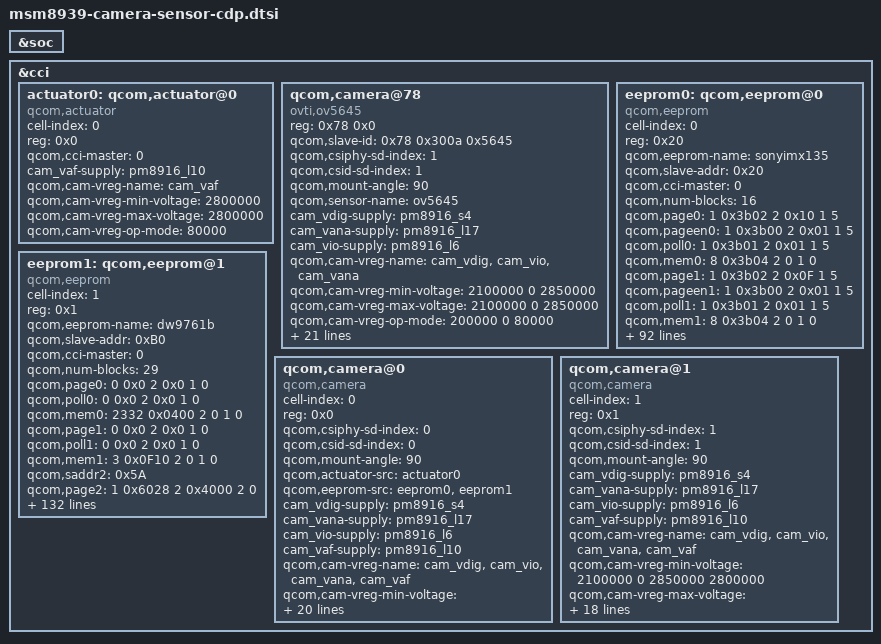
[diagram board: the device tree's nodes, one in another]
/*
 * Copyright (c) 2014-2015, The Linux Foundation. All rights reserved.
 *
 * This program is free software; you can redistribute it and/or modify
 * it under the terms of the GNU General Public License version 2 and
 * only version 2 as published by the Free Software Foundation.
 *
 * This program is distributed in the hope that it will be useful,
 * but WITHOUT ANY WARRANTY; without even the implied warranty of
 * MERCHANTABILITY or FITNESS FOR A PARTICULAR PURPOSE.  See the
 * GNU General Public License for more details.
 */

&soc {
};

&cci {

	actuator0: qcom,actuator@0 {
		cell-index = <0>;
		reg = <0x0>;
		compatible = "qcom,actuator";
		qcom,cci-master = <0>;
		cam_vaf-supply = <&pm8916_l10>;
		qcom,cam-vreg-name = "cam_vaf";
		qcom,cam-vreg-min-voltage = <2800000>;
		qcom,cam-vreg-max-voltage = <2800000>;
		qcom,cam-vreg-op-mode = <80000>;
	};

	qcom,camera@78 {
		compatible = "ovti,ov5645";
		reg = <0x78 0x0>;
		qcom,slave-id = <0x78 0x300a 0x5645>;
		qcom,csiphy-sd-index = <1>;
		qcom,csid-sd-index = <1>;
		qcom,mount-angle = <90>;
		qcom,sensor-name = "ov5645";
		cam_vdig-supply = <&pm8916_s4>;
		cam_vana-supply = <&pm8916_l17>;
		cam_vio-supply = <&pm8916_l6>;
		qcom,cam-vreg-name = "cam_vdig", "cam_vio", "cam_vana";
		qcom,cam-vreg-min-voltage = <2100000 0 2850000>;
		qcom,cam-vreg-max-voltage = <2100000 0 2850000>;
		qcom,cam-vreg-op-mode = <200000 0 80000>;
		pinctrl-names = "cam_default", "cam_suspend";
		pinctrl-0 = <&cam_sensor_mclk1_default
				&cam_sensor_front_default>;
		pinctrl-1 = <&cam_sensor_mclk1_sleep &cam_sensor_front_sleep>;
		gpios = <&msm_gpio 27 0>,
			<&msm_gpio 28 0>,
			<&msm_gpio 33 0>;
		qcom,gpio-reset = <1>;
		qcom,gpio-standby = <2>;
		qcom,gpio-req-tbl-num = <0 1 2>;
		qcom,gpio-req-tbl-flags = <1 0 0>;
		qcom,gpio-req-tbl-label = "CAMIF_MCLK",
					"CAM_RESET",
					"CAM_STANDBY";
		qcom,gpio-set-tbl-num = <1 1>;
		qcom,gpio-set-tbl-flags = <0 2>;
		qcom,gpio-set-tbl-delay = <1000 4000>;
		qcom,csi-lane-assign = <0x4320>;
		qcom,csi-lane-mask = <0x3>;
		qcom,sensor-position = <1>;
		qcom,sensor-mode = <0>;
		qcom,cci-master = <0>;
		clocks = <&clock_gcc clk_mclk1_clk_src>,
				<&clock_gcc clk_gcc_camss_mclk1_clk>;
		clock-names = "cam_src_clk", "cam_clk";
	};

	eeprom0: qcom,eeprom@0 {
		cell-index = <0>;
		reg = <0x20>;
		qcom,eeprom-name = "sonyimx135";
		compatible = "qcom,eeprom";
		qcom,slave-addr = <0x20>;
		qcom,cci-master = <0>;
		qcom,num-blocks = <16>;

		qcom,page0 = <1 0x3b02 2 0x10 1 5>;
		qcom,pageen0 = <1 0x3b00 2 0x01 1 5>;
		qcom,poll0 = <1 0x3b01 2 0x01 1 5>;
		qcom,mem0 = <8 0x3b04 2 0 1 0>;

		qcom,page1 = <1 0x3b02 2 0x0F 1 5>;
		qcom,pageen1 = <1 0x3b00 2 0x01 1 5>;
		qcom,poll1 = <1 0x3b01 2 0x01 1 5>;
		qcom,mem1 = <8 0x3b04 2 0 1 0>;

		qcom,page2 = <1 0x3b02 2 0x0E 1 5>;
		qcom,pageen2 = <1 0x3b00 2 0x01 1 5>;
		qcom,poll2 = <1 0x3b01 2 0x01 1 5>;
		qcom,mem2 = <8 0x3b04 2 0 1 0>;

		qcom,page3 = <1 0x3b02 2 0x0D 1 5>;
		qcom,pageen3 = <1 0x3b00 2 0x01 1 5>;
		qcom,poll3 = <1 0x3b01 2 0x01 1 5>;
		qcom,mem3 = <8 0x3b04 2 0 1 0>;

		qcom,page4 = <1 0x3b02 2 0x12 1 5>;
		qcom,pageen4 = <1 0x3b00 2 0x01 1 5>;
		qcom,poll4 = <1 0x3b01 2 0x01 1 5>;
		qcom,mem4 = <7 0x3b09 2 0 1 0>;

		qcom,page5 = <1 0x3b02 2 0x11 1 5>;
		qcom,pageen5 = <1 0x3b00 2 0x01 1 5>;
		qcom,poll5 = <1 0x3b01 2 0x01 1 5>;
		qcom,mem5 = <7 0x3b09 2 0 1 0>;

		qcom,page6 = <1 0x3b02 2 0x10 1 5>;
		qcom,pageen6 = <1 0x3b00 2 0x01 1 5>;
		qcom,poll6 = <1 0x3b01 2 0x01 1 5>;
		qcom,mem6 = <7 0x3b09 2 0 1 0>;

		qcom,page7 = <1 0x3b02 2 0x09 1 5>;
		qcom,pageen7 = <1 0x3b00 2 0x01 1 5>;
		qcom,poll7 = <1 0x3b01 2 0x01 1 5>;
		qcom,mem7 = <7 0x3b09 2 0 1 0>;

		qcom,page8 = <1 0x3b02 2 0x01 1 5>;
		qcom,pageen8 = <1 0x3b00 2 0x01 1 5>;
		qcom,poll8 = <1 0x3b01 2 0x01 1 5>;
		qcom,mem8 = <64 0x3b04 2 0 1 0>;

		qcom,page9 = <1 0x3b02 2 0x02 1 5>;
		qcom,pageen9 = <1 0x3b00 2 0x01 1 5>;
		qcom,poll9 = <1 0x3b01 2 0x01 1 5>;
		qcom,mem9 = <64 0x3b04 2 0 1 0>;

		qcom,page10 = <1 0x3b02 2 0x03 1 5>;
		qcom,pageen10 = <1 0x3b00 2 0x01 1 5>;
		qcom,poll10 = <1 0x3b01 2 0x01 1 5>;
		qcom,mem10 = <64 0x3b04 2 0 1 0>;

		qcom,page11 = <1 0x3b02 2 0x04 1 5>;
		qcom,pageen11 = <1 0x3b00 2 0x01 1 5>;
		qcom,poll11 = <1 0x3b01 2 0x01 1 5>;
		qcom,mem11 = <64 0x3b04 2 0 1 0>;

		qcom,page12 = <1 0x3b02 2 0x05 1 5>;
		qcom,pageen12 = <1 0x3b00 2 0x01 1 5>;
		qcom,poll12 = <1 0x3b01 2 0x01 1 5>;
		qcom,mem12 = <64 0x3b04 2 0 1 0>;

		qcom,page13 = <1 0x3b02 2 0x06 1 5>;
		qcom,pageen13 = <1 0x3b00 2 0x01 1 5>;
		qcom,poll13 = <1 0x3b01 2 0x01 1 5>;
		qcom,mem13 = <64 0x3b04 2 0 1 0>;

		qcom,page14 = <1 0x3b02 2 0x07 1 5>;
		qcom,pageen14 = <1 0x3b00 2 0x01 1 5>;
		qcom,poll14 = <1 0x3b01 2 0x01 1 5>;
		qcom,mem14 = <64 0x3b04 2 0 1 0>;

		qcom,page15 = <1 0x3b02 2 0x08 1 5>;
		qcom,pageen15 = <1 0x3b00 2 0x01 1 5>;
		qcom,poll15 = <1 0x3b01 2 0x01 1 5>;
		qcom,mem15 = <56 0x3b04 2 0 1 0>;

		cam_vdig-supply = <&pm8916_s4>;
		cam_vio-supply = <&pm8916_l17>;
		cam_vana-supply = <&pm8916_l6>;
		cam_vaf-supply = <&pm8916_l10>;
		qcom,cam-vreg-name = "cam_vdig", "cam_vio", "cam_vana", "cam_vaf";
		qcom,cam-vreg-min-voltage = <2100000 0 1800000 2800000>;
		qcom,cam-vreg-max-voltage = <2100000 0 1800000 2800000>;
		qcom,cam-vreg-op-mode = <200000 0 80000 100000>;
		pinctrl-names = "cam_default", "cam_suspend";
		pinctrl-0 = <&cam_sensor_mclk0_default &cam_sensor_rear_default>;
		pinctrl-1 = <&cam_sensor_mclk0_sleep &cam_sensor_rear_sleep>;
		qcom,gpio-no-mux = <0>;
		gpios = <&msm_gpio 26 0>,
			<&msm_gpio 35 0>,
			<&msm_gpio 34 0>;
		qcom,gpio-reset = <1>;
		qcom,gpio-standby = <2>;
		qcom,gpio-req-tbl-num = <0 1 2>;
		qcom,gpio-req-tbl-flags = <1 0 0>;
		qcom,gpio-req-tbl-label = "CAMIF_MCLK0",
			"CAM_RESET0",
			"CAM_STANDBY0";
		qcom,gpio-set-tbl-num = <1 1>;
		qcom,gpio-set-tbl-flags = <0 2>;
		qcom,gpio-set-tbl-delay = <1000 4000>;

		qcom,cam-power-seq-type = "sensor_vreg", "sensor_vreg", "sensor_vreg",
			"sensor_vreg", "sensor_gpio", "sensor_clk";
		qcom,cam-power-seq-val = "cam_vdig", "cam_vana", "cam_vio", "cam_vaf",
			"sensor_gpio_reset", "sensor_cam_mclk";
		qcom,cam-power-seq-cfg-val = <1 1 1 1 1 24000000>;
		qcom,cam-power-seq-delay = <1 1 1 1 30 5>;
		clocks = <&clock_gcc clk_mclk0_clk_src>,
				<&clock_gcc clk_gcc_camss_mclk0_clk>;
		clock-names = "cam_src_clk", "cam_clk";
	};

	eeprom1: qcom,eeprom@1 {
		cell-index = <1>;
		reg = <0x1>;
		qcom,eeprom-name = "dw9761b";
		compatible = "qcom,eeprom";
		qcom,slave-addr = <0xB0>;
		qcom,cci-master = <0>;
		qcom,num-blocks = <29>;
		qcom,page0 = <0 0x0 2 0x0 1 0>;
		qcom,poll0 = <0 0x0 2 0x0 1 0>;
		qcom,mem0 = <2332 0x0400 2 0 1 0>;

		qcom,page1 = <0 0x0 2 0x0 1 0>;
		qcom,poll1 = <0 0x0 2 0x0 1 0>;
		qcom,mem1 = <3 0x0F10 2 0 1 0>;

		/* bpc: insensor bpc */
		qcom,saddr2 = <0x5A>;
		qcom,page2 = <1 0x6028 2 0x4000 2 0>;
		qcom,poll2 = <0 0x0 2 0x0 2 0>;
		qcom,mem2 = <0 0x0 2 0x0 1 0>;

		qcom,page3 = <1 0x0136 2 0x1800 2 0>;
		qcom,poll3 = <0 0x0 2 0x0 2 0>;
		qcom,mem3 = <0 0x0 2 0x0 1 0>;

		qcom,page4 = <1 0x0304 2 0x0006 2 0>;
		qcom,poll4 = <0 0x0 2 0x0 2 0>;
		qcom,mem4 = <0 0x0 2 0x0 1 0>;

		qcom,page5 = <1 0x0306 2 0x0073 2 0>;
		qcom,poll5 = <0 0x0 2 0x0 2 0>;
		qcom,mem5 = <0 0x0 2 0x0 1 0>;

		qcom,page6 = <1 0x030C 2 0x0004 2 0>;
		qcom,poll6 = <0 0x0 2 0x0 2 0>;
		qcom,mem6 = <0 0x0 2 0x0 1 0>;

		qcom,page7 = <1 0x030E 2 0x0064 2 0>;
		qcom,poll7 = <0 0x0 2 0x0 2 0>;
		qcom,mem7 = <0 0x0 2 0x0 1 0>;

		qcom,page8 = <1 0x0302 2 0x0001 2 0>;
		qcom,poll8 = <0 0x0 2 0x0 2 0>;
		qcom,mem8 = <0 0x0 2 0x0 1 0>;

		qcom,page9 = <1 0x0300 2 0x0004 2 0>;
		qcom,poll9 = <0 0x0 2 0x0 2 0>;
		qcom,mem9 = <0 0x0 2 0x0 1 0>;

		qcom,page10 = <1 0x030A 2 0x0001 2 0>;
		qcom,poll10 = <0 0x0 2 0x0 2 0>;
		qcom,mem10 = <0 0x0 2 0x0 1 0>;

		qcom,page11 = <1 0x0308 2 0x0008 2 0>;
		qcom,poll11 = <0 0x0 2 0x0 2 0>;
		qcom,mem11 = <0 0x0 2 0x0 1 0>;

		qcom,page12 = <1 0x0100 2 0x0100 2 10>;
		qcom,poll12 = <0 0x0 2 0x0 2 0>;
		qcom,mem12 = <0 0x0 2 0x0 1 0>;

		qcom,page13 = <1 0x0A02 2 0x0D 1 0>;
		qcom,pageen13 = <1 0x0A00 2 0x01 1 0>;
		qcom,poll13 = <0 0x0 2 0x0 2 0>;
		qcom,mem13 = <64 0xA04 2 0x0 1 0>;

		qcom,page14 = <1 0x0A02 2 0x0E 1 0>;
		qcom,pageen14 = <1 0x0A00 2 0x01 1 0>;
		qcom,poll14 = <0 0x0 2 0x0 2 0>;
		qcom,mem14 = <64 0xA04 2 0x0 1 0>;

		qcom,page15 = <1 0x0A02 2 0x0F 1 0>;
		qcom,pageen15 = <1 0x0A00 2 0x01 1 0>;
		qcom,poll15 = <0 0x0 2 0x0 2 0>;
		qcom,mem15 = <64 0xA04 2 0x0 1 0>;

		qcom,page16 = <1 0x0A02 2 0x10 1 0>;
		qcom,pageen16 = <1 0x0A00 2 0x01 1 0>;
		qcom,poll16 = <0 0x0 2 0x0 2 0>;
		qcom,mem16 = <64 0xA04 2 0x0 1 0>;

		qcom,page17 = <1 0x0A02 2 0x11 1 0>;
		qcom,pageen17 = <1 0x0A00 2 0x01 1 0>;
		qcom,poll17 = <0 0x0 2 0x0 2 0>;
		qcom,mem17 = <64 0xA04 2 0x0 1 0>;

		qcom,page18 = <1 0x0A02 2 0x12 1 0>;
		qcom,pageen18 = <1 0x0A00 2 0x01 1 0>;
		qcom,poll18 = <0 0x0 2 0x0 2 0>;
		qcom,mem18 = <64 0xA04 2 0x0 1 0>;

		qcom,page19 = <1 0x0A02 2 0x13 1 0>;
		qcom,pageen19 = <1 0x0A00 2 0x01 1 0>;
		qcom,poll19 = <0 0x0 2 0x0 2 0>;
		qcom,mem19 = <64 0xA04 2 0x0 1 0>;

		qcom,page20 = <1 0x0A02 2 0x14 1 0>;
		qcom,pageen20 = <1 0x0A00 2 0x01 1 0>;
		qcom,poll20 = <0 0x0 2 0x0 2 0>;
		qcom,mem20 = <64 0xA04 2 0x0 1 0>;

		qcom,page21 = <1 0x0A02 2 0x15 1 0>;
		qcom,pageen21 = <1 0x0A00 2 0x01 1 0>;
		qcom,poll21 = <0 0x0 2 0x0 2 0>;
		qcom,mem21 = <64 0xA04 2 0x0 1 0>;

		qcom,page22 = <1 0x0A02 2 0x16 1 0>;
		qcom,pageen22 = <1 0x0A00 2 0x01 1 0>;
		qcom,poll22 = <0 0x0 2 0x0 2 0>;
		qcom,mem22 = <64 0xA04 2 0x0 1 0>;

		qcom,page23 = <1 0x0A02 2 0x17 1 0>;
		qcom,pageen23 = <1 0x0A00 2 0x01 1 0>;
		qcom,poll23 = <0 0x0 2 0x0 2 0>;
		qcom,mem23 = <64 0xA04 2 0x0 1 0>;

		qcom,page24 = <1 0x0A02 2 0x18 1 0>;
		qcom,pageen24 = <1 0x0A00 2 0x01 1 0>;
		qcom,poll24 = <0 0x0 2 0x0 2 0>;
		qcom,mem24 = <64 0xA04 2 0x0 1 0>;

		qcom,page25 = <1 0x0A02 2 0x19 1 0>;
		qcom,pageen25 = <1 0x0A00 2 0x01 1 0>;
		qcom,poll25 = <0 0x0 2 0x0 2 0>;
		qcom,mem25 = <64 0xA04 2 0x0 1 0>;

		qcom,page26 = <1 0x0A02 2 0x1A 1 0>;
		qcom,pageen26 = <1 0x0A00 2 0x01 1 0>;
		qcom,poll26 = <0 0x0 2 0x0 2 0>;
		qcom,mem26 = <64 0xA04 2 0x0 1 0>;

		qcom,page27 = <1 0x0A02 2 0x1B 1 0>;
		qcom,pageen27 = <1 0x0A00 2 0x01 1 0>;
		qcom,poll27 = <0 0x0 2 0x0 2 0>;
		qcom,mem27 = <64 0xA04 2 0x0 1 0>;

		qcom,page28 = <1 0x0A02 2 0x1C 1 0>;
		qcom,pageen28 = <1 0x0A00 2 0x01 1 0>;
		qcom,poll28 = <0 0x0 2 0x0 2 0>;
		qcom,mem28 = <60 0xA04 2 0x0 1 0>;

		cam_vdig-supply = <&pm8916_s4>;
		cam_vio-supply = <&pm8916_l17>;
		cam_vana-supply = <&pm8916_l6>;
		cam_vaf-supply = <&pm8916_l10>;
		qcom,cam-vreg-name = "cam_vdig", "cam_vio", "cam_vana", "cam_vaf";
		qcom,cam-vreg-min-voltage = <2100000 0 1800000 2800000>;
		qcom,cam-vreg-max-voltage = <2100000 0 1800000 2800000>;
		qcom,cam-vreg-op-mode = <200000 0 80000 100000>;
		pinctrl-names = "cam_default", "cam_suspend";
		pinctrl-0 = <&cam_sensor_mclk0_default &cam_sensor_rear_default>;
		pinctrl-1 = <&cam_sensor_mclk0_sleep &cam_sensor_rear_sleep>;
		qcom,gpio-no-mux = <0>;
		gpios = <&msm_gpio 26 0>,
			<&msm_gpio 35 0>,
			<&msm_gpio 34 0>;
		qcom,gpio-reset = <1>;
		qcom,gpio-standby = <2>;
		qcom,gpio-req-tbl-num = <0 1 2>;
		qcom,gpio-req-tbl-flags = <1 0 0>;
		qcom,gpio-req-tbl-label = "CAMIF_MCLK0",
			"CAM_RESET0",
			"CAM_STANDBY0";
		qcom,gpio-set-tbl-num = <1 1>;
		qcom,gpio-set-tbl-flags = <0 2>;
		qcom,gpio-set-tbl-delay = <1000 4000>;

		qcom,cam-power-seq-type = "sensor_vreg", "sensor_vreg", "sensor_vreg",
			"sensor_vreg", "sensor_gpio", "sensor_clk";
		qcom,cam-power-seq-val = "cam_vdig", "cam_vana", "cam_vio", "cam_vaf",
			"sensor_gpio_reset", "sensor_cam_mclk";
		qcom,cam-power-seq-cfg-val = <1 1 1 1 1 24000000>;
		qcom,cam-power-seq-delay = <1 1 1 1 30 5>;
		clocks = <&clock_gcc clk_mclk0_clk_src>,
				<&clock_gcc clk_gcc_camss_mclk0_clk>;
		clock-names = "cam_src_clk", "cam_clk";
	};

	qcom,camera@0 {
		cell-index = <0>;
		compatible = "qcom,camera";
		reg = <0x0>;
		qcom,csiphy-sd-index = <0>;
		qcom,csid-sd-index = <0>;
		qcom,mount-angle = <90>;
		qcom,actuator-src = <&actuator0>;
		qcom,eeprom-src = <&eeprom0 &eeprom1>;
		cam_vdig-supply = <&pm8916_s4>;
		cam_vana-supply = <&pm8916_l17>;
		cam_vio-supply = <&pm8916_l6>;
		cam_vaf-supply = <&pm8916_l10>;
		qcom,cam-vreg-name = "cam_vdig", "cam_vio", "cam_vana",
							"cam_vaf";
		qcom,cam-vreg-min-voltage = <2100000 0 2850000 2800000>;
		qcom,cam-vreg-max-voltage = <2100000 0 2850000 2800000>;
		qcom,cam-vreg-op-mode = <200000 0 80000 100000>;
		pinctrl-names = "cam_default", "cam_suspend";
		pinctrl-0 = <&cam_sensor_mclk0_default
				&cam_sensor_rear_default>;
		pinctrl-1 = <&cam_sensor_mclk0_sleep &cam_sensor_rear_sleep>;
		gpios = <&msm_gpio 26 0>,
			<&msm_gpio 35 0>,
			<&msm_gpio 34 0>;
		qcom,gpio-reset = <1>;
		qcom,gpio-standby = <2>;
		qcom,gpio-req-tbl-num = <0 1 2>;
		qcom,gpio-req-tbl-flags = <1 0 0>;
		qcom,gpio-req-tbl-label = "CAMIF_MCLK0",
			"CAM_RESET0",
			"CAM_STANDBY0";
		qcom,sensor-position = <0>;
		qcom,sensor-mode = <0>;
		qcom,cci-master = <0>;
		status = "ok";
		clocks = <&clock_gcc clk_mclk0_clk_src>,
				<&clock_gcc clk_gcc_camss_mclk0_clk>;
		clock-names = "cam_src_clk", "cam_clk";
	};

	qcom,camera@1 {
		cell-index = <1>;
		compatible = "qcom,camera";
		reg = <0x1>;
		qcom,csiphy-sd-index = <1>;
		qcom,csid-sd-index = <1>;
		qcom,mount-angle = <90>;
		cam_vdig-supply = <&pm8916_s4>;
		cam_vana-supply = <&pm8916_l17>;
		cam_vio-supply = <&pm8916_l6>;
		cam_vaf-supply = <&pm8916_l10>;
		qcom,cam-vreg-name = "cam_vdig", "cam_vio", "cam_vana",
							"cam_vaf";
		qcom,cam-vreg-min-voltage = <2100000 0 2850000 2800000>;
		qcom,cam-vreg-max-voltage = <2100000 0 2850000 2800000>;
		qcom,cam-vreg-op-mode = <200000 0 80000 100000>;
		pinctrl-names = "cam_default", "cam_suspend";
		pinctrl-0 = <&cam_sensor_mclk1_default &cam_sensor_front_default>;
		pinctrl-1 = <&cam_sensor_mclk1_sleep &cam_sensor_front_sleep>;
		gpios = <&msm_gpio 27 0>,
			<&msm_gpio 28 0>,
			<&msm_gpio 33 0>;
		qcom,gpio-reset = <1>;
		qcom,gpio-standby = <2>;
		qcom,gpio-req-tbl-num = <0 1 2>;
		qcom,gpio-req-tbl-flags = <1 0 0>;
		qcom,gpio-req-tbl-label = "CAMIF_MCLK1",
			"CAM_RESET1",
			"CAM_STANDBY1";
		qcom,sensor-position = <1>;
		qcom,sensor-mode = <0>;
		qcom,cci-master = <0>;
		status = "ok";
		clocks = <&clock_gcc clk_mclk1_clk_src>,
				<&clock_gcc clk_gcc_camss_mclk1_clk>;
		clock-names = "cam_src_clk", "cam_clk";
	};
};
